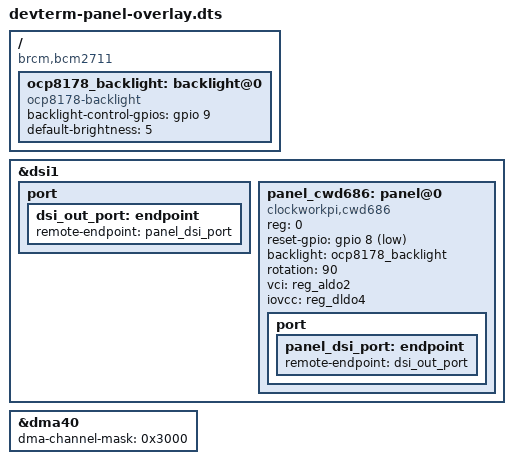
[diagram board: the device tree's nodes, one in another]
/dts-v1/;
/plugin/;

/ {
	compatible = "brcm,bcm2711";
	
	fragment@0 {
		target=<&dsi1>;
		__overlay__ {
			#address-cells = <1>;
			#size-cells = <0>;
			status = "okay";
			
			port {
				dsi_out_port: endpoint {
					remote-endpoint = <&panel_dsi_port>;
				};
			};
			
			panel_cwd686: panel@0 {
				compatible = "clockworkpi,cwd686";
				reg = <0>;
				reset-gpio = <&gpio 8 1>;
				backlight = <&ocp8178_backlight>;
				rotation = <90>;
				vci = <&reg_aldo2>;
				iovcc = <&reg_dldo4>;
				
				port {
					panel_dsi_port: endpoint {
						remote-endpoint = <&dsi_out_port>;
					};
				};
			};
		};
	};
	
	fragment@1 {
		target-path = "/";
		__overlay__  {
			ocp8178_backlight: backlight@0 {
				compatible = "ocp8178-backlight";
				backlight-control-gpios = <&gpio 9 0>;
				default-brightness = <5>;
			};
		};
	};
	
	fragment@2 {
		target = <&dma40>;
		__overlay__ {
			dma-channel-mask = <0x3000>;
		};
	};
};
